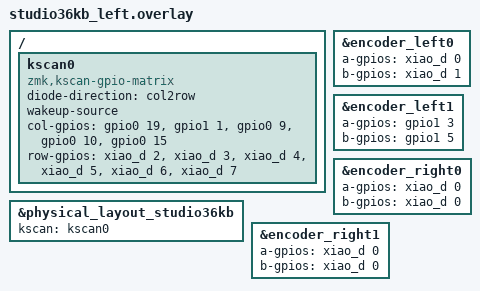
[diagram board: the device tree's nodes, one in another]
#include "studio36kb.dtsi"

/ {
    kscan0: kscan0 {
        compatible = "zmk,kscan-gpio-matrix";
        diode-direction = "col2row";
        wakeup-source;

        col-gpios
            = <&gpio0 19 GPIO_ACTIVE_HIGH>
            , <&gpio1 1 GPIO_ACTIVE_HIGH>
            , <&gpio0 9 GPIO_ACTIVE_HIGH>
            , <&gpio0 10 GPIO_ACTIVE_HIGH>
            , <&gpio0 15 GPIO_ACTIVE_HIGH>
            ;

        row-gpios
            = <&xiao_d 2 (GPIO_ACTIVE_HIGH | GPIO_PULL_DOWN)>
            , <&xiao_d 3 (GPIO_ACTIVE_HIGH | GPIO_PULL_DOWN)>
            , <&xiao_d 4 (GPIO_ACTIVE_HIGH | GPIO_PULL_DOWN)>
            , <&xiao_d 5 (GPIO_ACTIVE_HIGH | GPIO_PULL_DOWN)>
            , <&xiao_d 6 (GPIO_ACTIVE_HIGH | GPIO_PULL_DOWN)>
            , <&xiao_d 7 (GPIO_ACTIVE_HIGH | GPIO_PULL_DOWN)>
            ;
    };
};

&physical_layout_studio36kb {
    kscan = <&kscan0>;
};

&encoder_left0 {
    a-gpios = <&xiao_d 0 (GPIO_ACTIVE_HIGH | GPIO_PULL_UP)>;
    b-gpios = <&xiao_d 1 (GPIO_ACTIVE_HIGH | GPIO_PULL_UP)>;
    status = "okay";
};
&encoder_left1 {
    a-gpios = <&gpio1 3 (GPIO_ACTIVE_HIGH | GPIO_PULL_UP)>;
    b-gpios = <&gpio1 5 (GPIO_ACTIVE_HIGH | GPIO_PULL_UP)>;
    status = "okay";
};

// Assigning dummy pins to other part's encoders
// just to satisfy the devicetree requirements.
// No code will be compiled for these disabled encoders.
&encoder_right0 {
    a-gpios = <&xiao_d 0 (GPIO_ACTIVE_HIGH | GPIO_PULL_UP)>;
    b-gpios = <&xiao_d 0 (GPIO_ACTIVE_HIGH | GPIO_PULL_UP)>;
};
&encoder_right1 {
    a-gpios = <&xiao_d 0 (GPIO_ACTIVE_HIGH | GPIO_PULL_UP)>;
    b-gpios = <&xiao_d 0 (GPIO_ACTIVE_HIGH | GPIO_PULL_UP)>;
};

